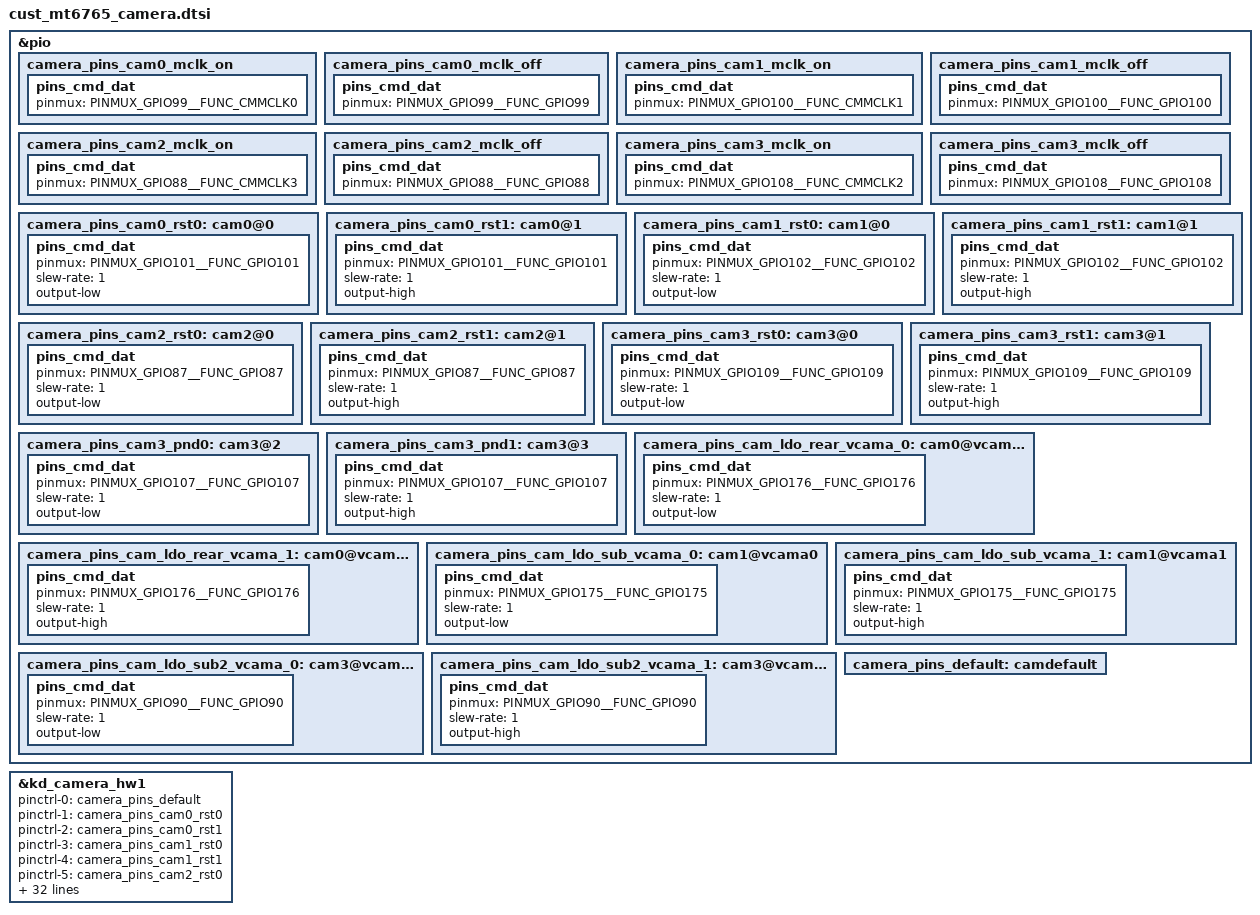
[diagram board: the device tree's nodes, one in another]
/*
 * Copyright (c) 2019 MediaTek Inc.
 *
 * This program is free software; you can redistribute it and/or modify
 * it under the terms of the GNU General Public License version 2 as
 * published by the Free Software Foundation.
 *
 * This program is distributed in the hope that it will be useful,
 * but WITHOUT ANY WARRANTY; without even the implied warranty of
 * MERCHANTABILITY or FITNESS FOR A PARTICULAR PURPOSE.  See the
 * GNU General Public License for more details.
 */
/* CAMERA GPIO standardization */
&pio {
	camera_pins_cam0_mclk_on: camera_pins_cam0_mclk_on {
		pins_cmd_dat {
			pinmux = <PINMUX_GPIO99__FUNC_CMMCLK0>;
		};
	};
	camera_pins_cam0_mclk_off: camera_pins_cam0_mclk_off {
		pins_cmd_dat {
			pinmux = <PINMUX_GPIO99__FUNC_GPIO99>;
		};
	};
	camera_pins_cam1_mclk_on: camera_pins_cam1_mclk_on {
		pins_cmd_dat {
			pinmux = <PINMUX_GPIO100__FUNC_CMMCLK1>;
		};
	};
	camera_pins_cam1_mclk_off: camera_pins_cam1_mclk_off {
		pins_cmd_dat {
			pinmux = <PINMUX_GPIO100__FUNC_GPIO100>;
		};
	};
	camera_pins_cam2_mclk_on: camera_pins_cam2_mclk_on {
		pins_cmd_dat {
			pinmux = <PINMUX_GPIO88__FUNC_CMMCLK3>;
		};
	};
	camera_pins_cam2_mclk_off: camera_pins_cam2_mclk_off {
		pins_cmd_dat {
			pinmux = <PINMUX_GPIO88__FUNC_GPIO88>;
		};
	};
	camera_pins_cam3_mclk_on: camera_pins_cam3_mclk_on {
		pins_cmd_dat {
			pinmux = <PINMUX_GPIO108__FUNC_CMMCLK2>;
		};
	};
	camera_pins_cam3_mclk_off: camera_pins_cam3_mclk_off {
		pins_cmd_dat {
			pinmux = <PINMUX_GPIO108__FUNC_GPIO108>;
		};
	};

	camera_pins_cam0_rst0: cam0@0 {
		pins_cmd_dat {
			pinmux = <PINMUX_GPIO101__FUNC_GPIO101>;
			slew-rate = <1>;
			output-low;
		};
	};
	camera_pins_cam0_rst1: cam0@1 {
		pins_cmd_dat {
			pinmux = <PINMUX_GPIO101__FUNC_GPIO101>;
			slew-rate = <1>;
			output-high;
		};
	};

	camera_pins_cam1_rst0: cam1@0 {
		pins_cmd_dat {
			pinmux = <PINMUX_GPIO102__FUNC_GPIO102>;
			slew-rate = <1>;
			output-low;
		};
	};
	camera_pins_cam1_rst1: cam1@1 {
		pins_cmd_dat {
			pinmux = <PINMUX_GPIO102__FUNC_GPIO102>;
			slew-rate = <1>;
			output-high;
		};
	};
	camera_pins_cam2_rst0: cam2@0 {
		pins_cmd_dat {
			pinmux = <PINMUX_GPIO87__FUNC_GPIO87>;
			slew-rate = <1>;
			output-low;
		};
	};
	camera_pins_cam2_rst1: cam2@1 {
		pins_cmd_dat {
			pinmux = <PINMUX_GPIO87__FUNC_GPIO87>;
			slew-rate = <1>;
			output-high;
		};
	};

	camera_pins_cam3_rst0: cam3@0 {
		pins_cmd_dat {
			pinmux = <PINMUX_GPIO109__FUNC_GPIO109>;
			slew-rate = <1>;
			output-low;
		};
	};
	camera_pins_cam3_rst1: cam3@1 {
		pins_cmd_dat {
			pinmux = <PINMUX_GPIO109__FUNC_GPIO109>;
			slew-rate = <1>;
			output-high;
		};
	};
	camera_pins_cam3_pnd0: cam3@2 {
		pins_cmd_dat {
			pinmux = <PINMUX_GPIO107__FUNC_GPIO107>;
			slew-rate = <1>;
			output-low;
		};
	};
	camera_pins_cam3_pnd1: cam3@3 {
		pins_cmd_dat {
			pinmux = <PINMUX_GPIO107__FUNC_GPIO107>;
			slew-rate = <1>;
			output-high;
		};
	};

	camera_pins_cam_ldo_rear_vcama_0: cam0@vcama0 {
		pins_cmd_dat {
			pinmux = <PINMUX_GPIO176__FUNC_GPIO176>;
			slew-rate = <1>;
			output-low;
		};
	};
	camera_pins_cam_ldo_rear_vcama_1: cam0@vcama1 {
		pins_cmd_dat {
			pinmux = <PINMUX_GPIO176__FUNC_GPIO176>;
			slew-rate = <1>;
			output-high;
		};
	};
	camera_pins_cam_ldo_sub_vcama_0: cam1@vcama0 {
		pins_cmd_dat {
			pinmux = <PINMUX_GPIO175__FUNC_GPIO175>;
			slew-rate = <1>;
			output-low;
		};
	};
	camera_pins_cam_ldo_sub_vcama_1: cam1@vcama1 {
		pins_cmd_dat {
			pinmux = <PINMUX_GPIO175__FUNC_GPIO175>;
			slew-rate = <1>;
			output-high;
		};
	};
	camera_pins_cam_ldo_sub2_vcama_0: cam3@vcama0 {
		pins_cmd_dat {
			pinmux = <PINMUX_GPIO90__FUNC_GPIO90>;
			slew-rate = <1>;
			output-low;
		};
	};
	camera_pins_cam_ldo_sub2_vcama_1: cam3@vcama1 {
		pins_cmd_dat {
			pinmux = <PINMUX_GPIO90__FUNC_GPIO90>;
			slew-rate = <1>;
			output-high;
		};
	};
	camera_pins_default: camdefault {
	};

};

&kd_camera_hw1 {
//	/delete-property/ pinctrl-names;
	pinctrl-names = "default",
			"cam0_rst0",
			"cam0_rst1",
			"cam1_rst0",
			"cam1_rst1",
			"cam2_rst0",
			"cam2_rst1",
			"cam3_rst0",
			"cam3_rst1",
			"cam3_pnd0",
			"cam3_pnd1",

			"cam0_vcama_on",
			"cam0_vcama_off",
			"cam1_vcama_on",
			"cam1_vcama_off",
			"cam3_vcama_on",
			"cam3_vcama_off",

			"cam0_mclk_on",
			"cam0_mclk_off",
			"cam1_mclk_on",
			"cam1_mclk_off",
			"cam2_mclk_on",
			"cam2_mclk_off",
			"cam3_mclk_on",
			"cam3_mclk_off";

	pinctrl-0 = <&camera_pins_default>;
	pinctrl-1 = <&camera_pins_cam0_rst0>;
	pinctrl-2 = <&camera_pins_cam0_rst1>;
	pinctrl-3 = <&camera_pins_cam1_rst0>;
	pinctrl-4 = <&camera_pins_cam1_rst1>;
	pinctrl-5 = <&camera_pins_cam2_rst0>;
	pinctrl-6 = <&camera_pins_cam2_rst1>;
	pinctrl-7 = <&camera_pins_cam3_rst0>;
	pinctrl-8 = <&camera_pins_cam3_rst1>;
	pinctrl-9 = <&camera_pins_cam3_pnd0>;
	pinctrl-10 = <&camera_pins_cam3_pnd1>;

	pinctrl-11 = <&camera_pins_cam_ldo_rear_vcama_1>;
	pinctrl-12 = <&camera_pins_cam_ldo_rear_vcama_0>;

	pinctrl-13 = <&camera_pins_cam_ldo_sub_vcama_1>;
	pinctrl-14 = <&camera_pins_cam_ldo_sub_vcama_0>;
	pinctrl-15 = <&camera_pins_cam_ldo_sub2_vcama_1>;
	pinctrl-16 = <&camera_pins_cam_ldo_sub2_vcama_0>;

	pinctrl-17 = <&camera_pins_cam0_mclk_on>;
	pinctrl-18 = <&camera_pins_cam0_mclk_off>;
	pinctrl-19 = <&camera_pins_cam1_mclk_on>;
	pinctrl-20 = <&camera_pins_cam1_mclk_off>;
	pinctrl-21 = <&camera_pins_cam2_mclk_on>;
	pinctrl-22 = <&camera_pins_cam2_mclk_off>;
	pinctrl-23 = <&camera_pins_cam3_mclk_on>;
	pinctrl-24 = <&camera_pins_cam3_mclk_off>;

	cam0_vcamio-supply = <&mt_pmic_vcamio_ldo_reg>;
	cam0_vcamd-supply = <&mt_pmic_vcamd_ldo_reg>;

	cam1_vcamio-supply = <&mt_pmic_vcamio_ldo_reg>;
	cam1_vcamd-supply = <&mt_pmic_vcamd_ldo_reg>;

	cam2_vcamio-supply = <&mt_pmic_vcamio_ldo_reg>;
	cam2_vcama-supply = <&mt_pmic_vcama_ldo_reg>;

	cam3_vcamio-supply = <&mt_pmic_vcamio_ldo_reg>;
	cam3_vcamd-supply = <&mt_pmic_vcamd_ldo_reg>;

	cam0_enable_sensor = "hi1634z6250cc142_mipi_raw";
	cam1_enable_sensor = "hi846z6250cc137_mipi_raw gc8034z6250cc137_mipi_raw";
	cam2_enable_sensor = "gc02m1bz6250cc098_mipi_raw";
	cam3_enable_sensor = "hi846z6250cc134_mipi_raw";
	status = "okay";

};
/* CAMERA GPIO end */
